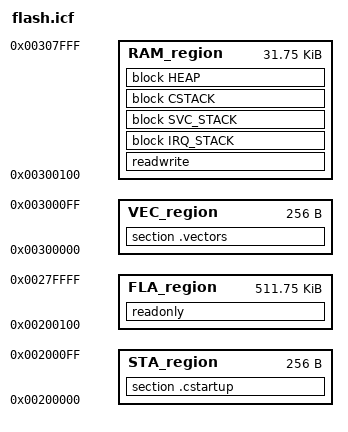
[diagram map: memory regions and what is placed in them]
/*###ICF### Section handled by ICF editor, don't touch! ****/
/*-Editor annotation file-*/
/* IcfEditorFile="$TOOLKIT_DIR$\config\ide\IcfEditor\a_v1_0.xml" */
/*-Memory Regions-*/
define symbol __ICFEDIT_region_FLA_start__   = 0x200000;
define symbol __ICFEDIT_region_FLA_end__     = 0x27FFFF;
define symbol __ICFEDIT_region_RAM_start__   = 0x300000;
define symbol __ICFEDIT_region_RAM_end__     = 0x307FFF;
/*-Sizes-*/
define symbol __ICFEDIT_size_startup__  = 0x100;
define symbol __ICFEDIT_size_vectors__  = 0x100;
define symbol __ICFEDIT_size_cstack__   = 0x1000;
define symbol __ICFEDIT_size_svcstack__ = 0x60;
define symbol __ICFEDIT_size_irqstack__ = 0x60;
/**** End of ICF editor section. ###ICF###*/

define memory mem with size = 4G;
define region VEC_region = mem:[from __ICFEDIT_region_RAM_start__ size __ICFEDIT_size_vectors__];
define region RAM_region = mem:[from __ICFEDIT_region_RAM_start__+__ICFEDIT_size_vectors__ to __ICFEDIT_region_RAM_end__];
define region STA_region = mem:[from __ICFEDIT_region_FLA_start__ size __ICFEDIT_size_startup__];
define region FLA_region = mem:[from __ICFEDIT_region_FLA_start__+__ICFEDIT_size_startup__ to __ICFEDIT_region_FLA_end__];

define block CSTACK    with alignment = 4, size = __ICFEDIT_size_cstack__   { };
define block SVC_STACK with alignment = 4, size = __ICFEDIT_size_svcstack__ { };
define block IRQ_STACK with alignment = 4, size = __ICFEDIT_size_irqstack__ { };
define block HEAP      with alignment = 4, size = 0 { };

initialize by copy { readwrite };
initialize by copy { section .vectors };
do not initialize  { section .noinit };

place in STA_region { section .cstartup };
place in VEC_region { section .vectors };
place in FLA_region { readonly };
place in RAM_region { readwrite, block IRQ_STACK, block SVC_STACK, block CSTACK, block HEAP };
